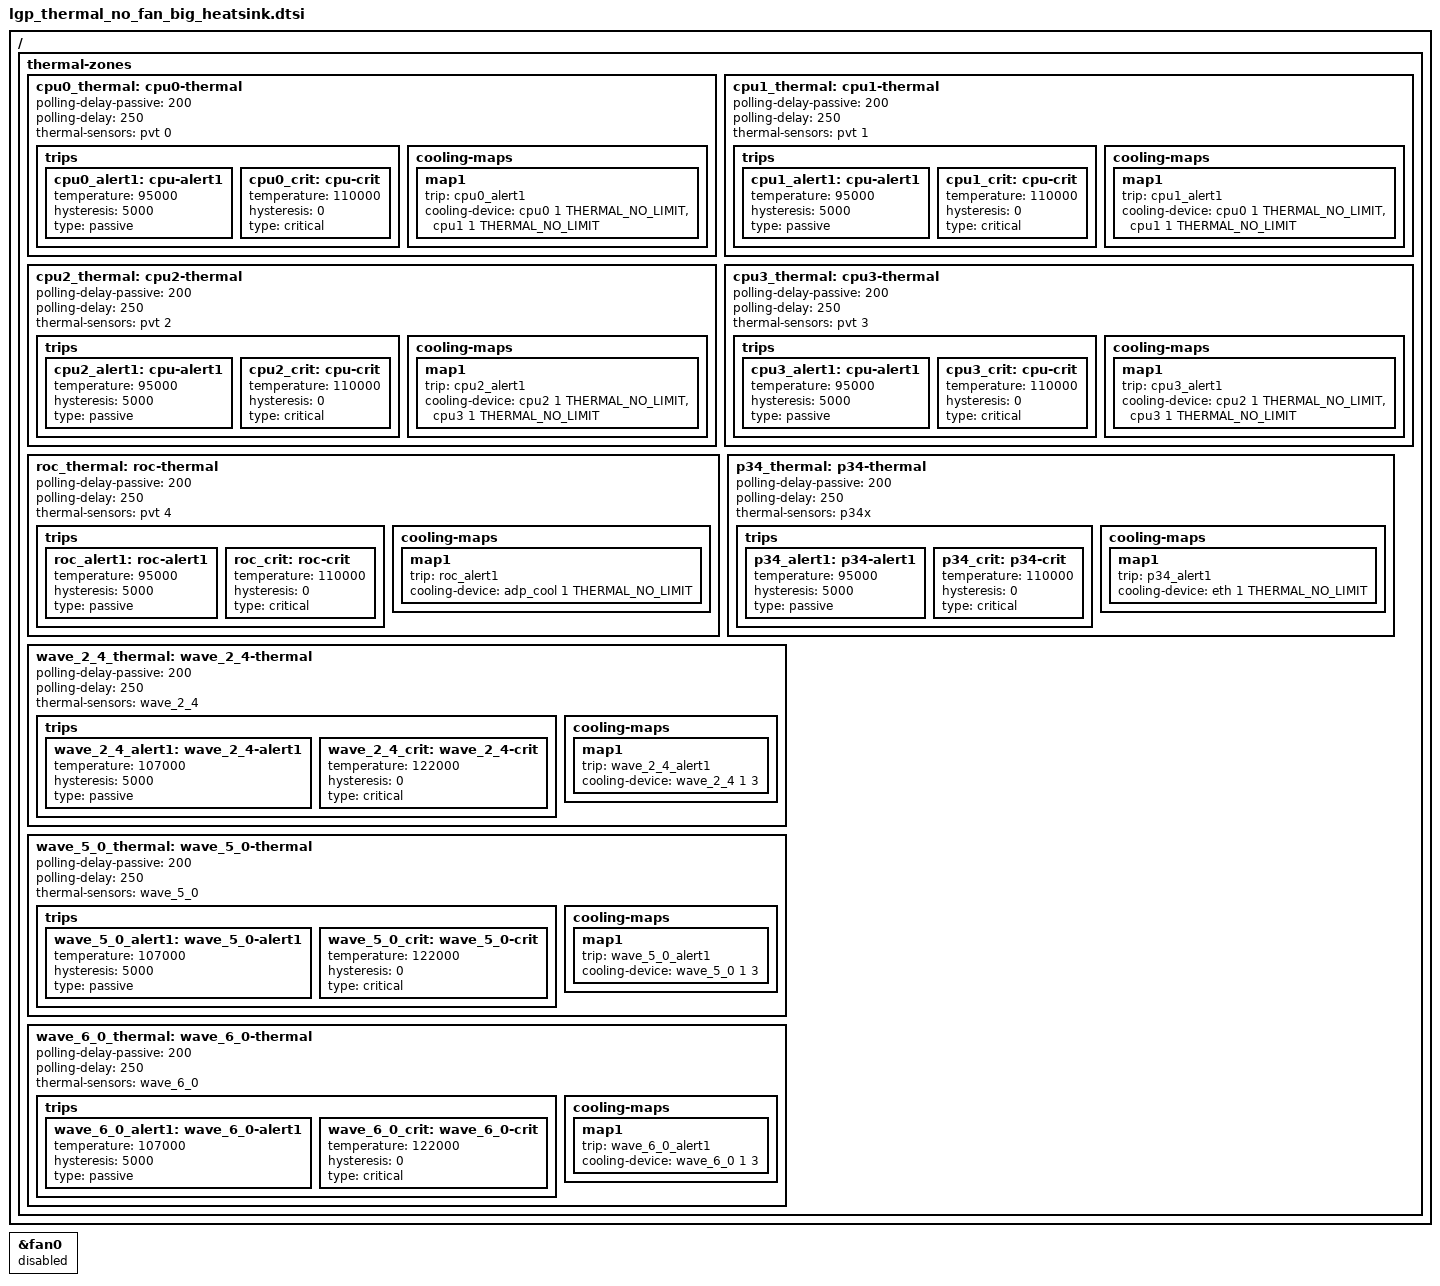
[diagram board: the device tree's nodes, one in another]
// SPDX-License-Identifier: GPL-2.0
/*
 * Copyright (C) 2020-2022 MaxLinear, Inc.
 * Copyright (c) 2019 Intel Corporation.
 */

#include <dt-bindings/thermal/thermal.h>

/ {
	/* thermal */
	thermal-zones {
		cpu0_thermal: cpu0-thermal {
			polling-delay-passive = <200>; /* milliseconds */
			polling-delay = <250>; /* milliseconds */

			thermal-sensors = <&pvt 0>;

			trips {
				cpu0_alert1: cpu-alert1 {
					temperature = <95000>; /* millicelsius */
					hysteresis = <5000>; /* millicelsius */
					type = "passive";
				};
				cpu0_crit: cpu-crit {
					temperature = <110000>; /* millicelsius */
					hysteresis = <0>; /* millicelsius */
					type = "critical";
				};
			};

			cooling-maps {
				map1 {
					trip = <&cpu0_alert1>;
					cooling-device = <&cpu0 1 THERMAL_NO_LIMIT>,
							 <&cpu1 1 THERMAL_NO_LIMIT>;
				};
			};
		};

		cpu1_thermal: cpu1-thermal {
			polling-delay-passive = <200>; /* milliseconds */
			polling-delay = <250>; /* milliseconds */

			thermal-sensors = <&pvt 1>;

			trips {
				cpu1_alert1: cpu-alert1 {
					temperature = <95000>; /* millicelsius */
					hysteresis = <5000>; /* millicelsius */
					type = "passive";
				};
				cpu1_crit: cpu-crit {
					temperature = <110000>; /* millicelsius */
					hysteresis = <0>; /* millicelsius */
					type = "critical";
				};
			};

			cooling-maps {
				map1 {
					trip = <&cpu1_alert1>;
					cooling-device = <&cpu0 1 THERMAL_NO_LIMIT>,
							 <&cpu1 1 THERMAL_NO_LIMIT>;
				};
			};
		};

		cpu2_thermal: cpu2-thermal {
			polling-delay-passive = <200>; /* milliseconds */
			polling-delay = <250>; /* milliseconds */

			thermal-sensors = <&pvt 2>;

			trips {
				cpu2_alert1: cpu-alert1 {
					temperature = <95000>; /* millicelsius */
					hysteresis = <5000>; /* millicelsius */
					type = "passive";
				};
				cpu2_crit: cpu-crit {
					temperature = <110000>; /* millicelsius */
					hysteresis = <0>; /* millicelsius */
					type = "critical";
				};
			};

			cooling-maps {
				map1 {
					trip = <&cpu2_alert1>;
					cooling-device = <&cpu2 1 THERMAL_NO_LIMIT>,
							 <&cpu3 1 THERMAL_NO_LIMIT>;
				};
			};
		};

		cpu3_thermal: cpu3-thermal {
			polling-delay-passive = <200>; /* milliseconds */
			polling-delay = <250>; /* milliseconds */

			thermal-sensors = <&pvt 3>;

			trips {
				cpu3_alert1: cpu-alert1 {
					temperature = <95000>; /* millicelsius */
					hysteresis = <5000>; /* millicelsius */
					type = "passive";
				};
				cpu3_crit: cpu-crit {
					temperature = <110000>; /* millicelsius */
					hysteresis = <0>; /* millicelsius */
					type = "critical";
				};
			};

			cooling-maps {
				map1 {
					trip = <&cpu3_alert1>;
					cooling-device = <&cpu2 1 THERMAL_NO_LIMIT>,
							 <&cpu3 1 THERMAL_NO_LIMIT>;
				};
			};
		};

		roc_thermal: roc-thermal {
			polling-delay-passive = <200>; /* milliseconds */
			polling-delay = <250>; /* milliseconds */

			thermal-sensors = <&pvt 4>;

			trips {
				roc_alert1: roc-alert1 {
					temperature = <95000>; /* millicelsius */
					hysteresis = <5000>; /* millicelsius */
					type = "passive";
				};
				roc_crit: roc-crit {
					temperature = <110000>; /* millicelsius */
					hysteresis = <0>; /* millicelsius */
					type = "critical";
				};
			};

			cooling-maps {
				map1 {
					trip = <&roc_alert1>;
					cooling-device = <&adp_cool 1 THERMAL_NO_LIMIT>;
				};
			};
		};

		p34_thermal: p34-thermal {
			polling-delay-passive = <200>; /* milliseconds */
			polling-delay = <250>; /* milliseconds */

			thermal-sensors = <&p34x>;

			trips {
				p34_alert1: p34-alert1 {
					temperature = <95000>; /* millicelsius */
					hysteresis = <5000>; /* millicelsius */
					type = "passive";
				};
				p34_crit: p34-crit {
					temperature = <110000>; /* millicelsius */
					hysteresis = <0>; /* millicelsius */
					type = "critical";
				};
			};

			cooling-maps {
				map1 {
					trip = <&p34_alert1>;
					cooling-device = <&eth 1 THERMAL_NO_LIMIT>;
				};
			};
		};
		wave_2_4_thermal: wave_2_4-thermal {
			polling-delay-passive = <200>; /* milliseconds */
			polling-delay = <250>; /* milliseconds */

			thermal-sensors = <&wave_2_4>;

			trips {
				wave_2_4_alert1: wave_2_4-alert1 {
					temperature = <107000>; /* millicelsius */
					hysteresis = <5000>; /* millicelsius */
					type = "passive";
				};
				wave_2_4_crit: wave_2_4-crit {
					temperature = <122000>;
					hysteresis = <0>;
					type = "critical";
				};
			};

			cooling-maps {
				map1 {
					trip = <&wave_2_4_alert1>;
					cooling-device = <&wave_2_4 1 3>;
				};
			};
		};

		wave_5_0_thermal: wave_5_0-thermal {
			polling-delay-passive = <200>; /* milliseconds */
			polling-delay = <250>; /* milliseconds */

			thermal-sensors = <&wave_5_0>;

			trips {
				wave_5_0_alert1: wave_5_0-alert1 {
					temperature = <107000>; /* millicelsius */
					hysteresis = <5000>; /* millicelsius */
					type = "passive";
				};
				wave_5_0_crit: wave_5_0-crit {
					temperature = <122000>;
					hysteresis = <0>;
					type = "critical";
				};
			};

			cooling-maps {
				map1 {
					trip = <&wave_5_0_alert1>;
					cooling-device = <&wave_5_0 1 3>;
				};
			};
		};

		wave_6_0_thermal: wave_6_0-thermal {
			polling-delay-passive = <200>; /* milliseconds */
			polling-delay = <250>; /* milliseconds */

			thermal-sensors = <&wave_6_0>;

			trips {
				wave_6_0_alert1: wave_6_0-alert1 {
					temperature = <107000>; /* millicelsius */
					hysteresis = <5000>; /* millicelsius */
					type = "passive";
				};
				wave_6_0_crit: wave_6_0-crit {
					temperature = <122000>;
					hysteresis = <0>;
					type = "critical";
				};
			};

			cooling-maps {
				map1 {
					trip = <&wave_6_0_alert1>;
					cooling-device = <&wave_6_0 1 3>;
				};
			};
		};
	};
};

&fan0 {
	status = "disabled";
};
